# Cortex_M0PLUS register map
Vendor: ARM Ltd.; File version: 1.2
Cortex-M0+ core descriptions, generated from ARM develloper studio
CPU: CM0PLUS r0p0, little endian, MPU, no FPU, vendor SysTick, 8 interrupt priority bits
Registers are 32-bit, read-write, reset 0x0 unless marked. A register's access mark holds for its fields unless they carry their own. Offsets are from the block's base; lines under a group give offsets from that group; [hi:lo] are bit positions; {n}, {i} and the like mark numbered series; 'fields as' and 'values as' point back to an identical list; <NAME> marks a mode.

## Memory map
0xE000E010 STK size 0x10 — System Timer registers
0xE000E100 NVIC size 0x320 — Nested Vectored Interrupt Controller
0xE000ED00 SCB size 0x24 — System control block
0xE000ED04 Control size 0xE0 — System Control registers
0xE000ED90 MPU size 0x14 — Memory Protection Unit registers

## Control — System Control registers
Base 0xE000ED04
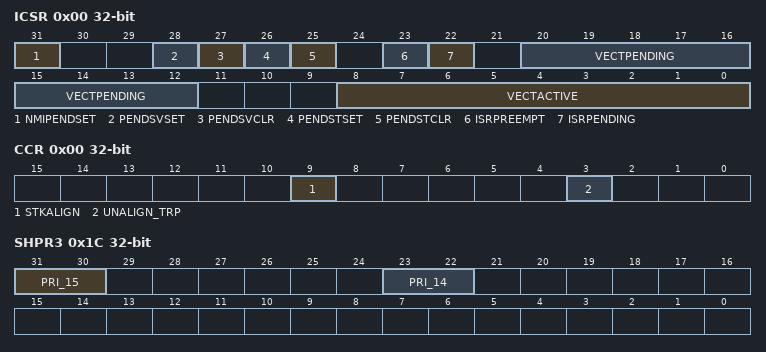
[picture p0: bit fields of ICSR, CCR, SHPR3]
0x00 ICSR reset not defined
  [31] NMIPENDSET
    0=Do_not_activate; 1=Activate_NMI_exception
  [28] PENDSVSET
    0=Do_not_set; 1=Set_pending
  [27] PENDSVCLR
    0=Do_not_clear; 1=Clear_pending
  [26] PENDSTSET
    0=Do_not_set; 1=Set_pending
  [25] PENDSTCLR
    0=Do_not_clear; 1=Clear_pending
  [23] ISRPREEMPT
    0=Will_not_service; 1=Will_service_pending_exception
  [22] ISRPENDING
    0=Interrupt_not_pending; 1=Interrupt_pending
  [20:12] VECTPENDING
  [8:0] VECTACTIVE
0x00 CCR ro reset not defined
  [9] STKALIGN, [3] UNALIGN_TRP
0x04 VTOR reset not defined
  [29] TBLBASE
    0=CODE; 1=SRAM
  [31:7] TBLOFF
0x08 AIRCR reset not defined
  [31:16] VECTKEY
  [31:16] VECTKEYSTAT
  [15] ENDIANNESS
    0=Little_endian; 1=Big_endian
  [2] SYSRESETREQ
    0=Do_not_request_reset; 1=Request_reset
  [1] VECTCLRACTIVE
    0=Do_not_clear; 1=Clear_state_information
0x18 SHPR2 reset not defined
  [31:30] PRI_11
0x1C SHPR3 reset not defined
  [31:30] PRI_15, [23:22] PRI_14
0x20 SHCSR reset not defined
  [15] SVCALLPENDED
    0=Not_pending; 1=Pending

## SCB — System control block
Base 0xE000ED00
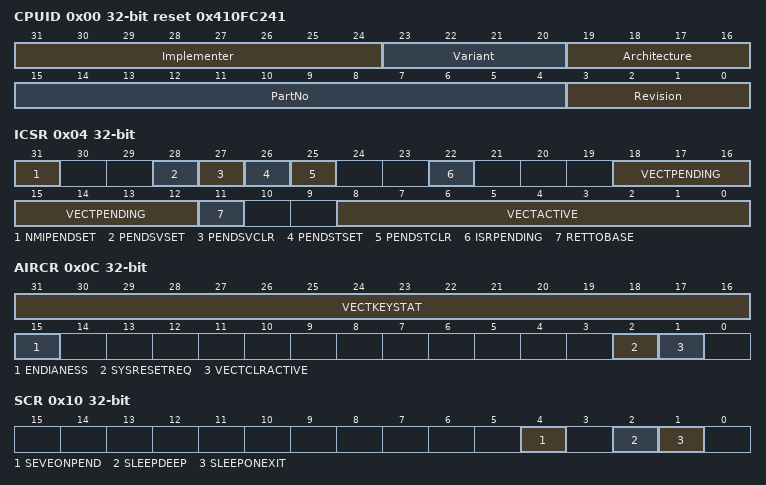
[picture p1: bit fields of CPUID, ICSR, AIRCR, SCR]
0x00 CPUID ro reset 0x410FC241 — CPUID base register
  [31:24] Implementer — Implementer code
  [23:20] Variant — Variant number
  [19:16] Architecture — Reads as 0xF
  [15:4] PartNo — Part number of the processor
  [3:0] Revision — Revision number
0x04 ICSR — Interrupt control and state register
  [31] NMIPENDSET — NMI set-pending bit.
  [28] PENDSVSET — PendSV set-pending bit
  [27] PENDSVCLR — PendSV clear-pending bit
  [26] PENDSTSET — SysTick exception set-pending bit
  [25] PENDSTCLR — SysTick exception clear-pending bit
  [22] ISRPENDING — Interrupt pending flag
  [18:12] VECTPENDING — Pending vector
  [11] RETTOBASE — Return to base level
  [8:0] VECTACTIVE — Active vector
0x08 VTOR — Vector table offset register
  [31:7] TBLOFF — Vector table base offset field
0x0C AIRCR — Application interrupt and reset control register
  [31:16] VECTKEYSTAT — Register key
  [15] ENDIANESS
  [2] SYSRESETREQ
  [1] VECTCLRACTIVE
0x10 SCR — System control register
  [4] SEVEONPEND — Send Event on Pending bit
  [2] SLEEPDEEP
  [1] SLEEPONEXIT
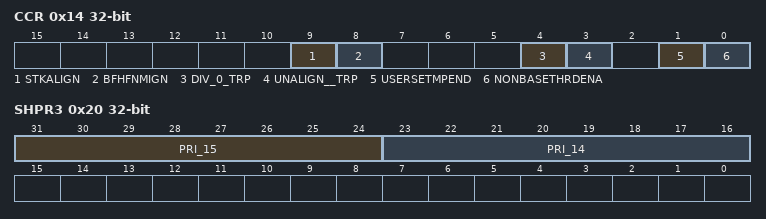
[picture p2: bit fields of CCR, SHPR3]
0x14 CCR — Configuration and control register
  [9] STKALIGN
  [8] BFHFNMIGN
  [4] DIV_0_TRP
  [3] UNALIGN__TRP
  [1] USERSETMPEND
  [0] NONBASETHRDENA — Configures how the processor enters Thread mode
0x1C SHPR2 — System handler priority registers
  [31:24] PRI_11 — Priority of system handler 11
0x20 SHPR3 — System handler priority registers
  [31:24] PRI_15 — Priority of system handler 15
  [23:16] PRI_14 — Priority of system handler 14

## MPU — Memory Protection Unit registers
Base 0xE000ED90
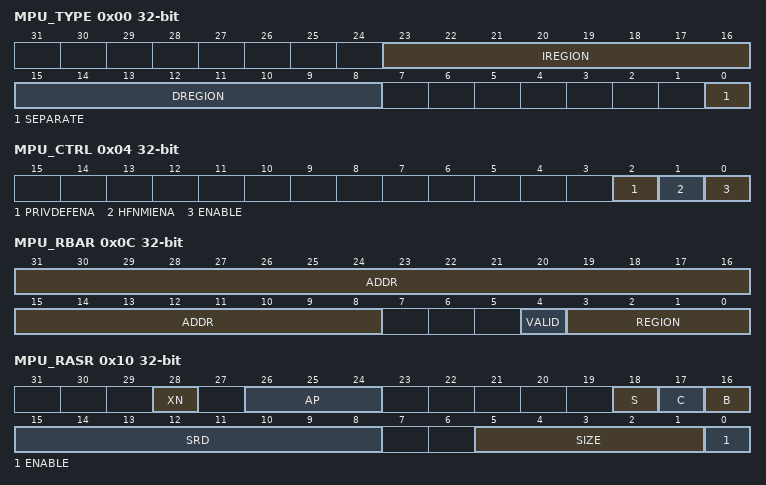
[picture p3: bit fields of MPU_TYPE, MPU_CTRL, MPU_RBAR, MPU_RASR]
0x00 MPU_TYPE ro reset not defined
  [23:16] IREGION, [15:8] DREGION, [0] SEPARATE
0x04 MPU_CTRL reset not defined — MPU Control Register
  [all] fields
    0=Disabled; 1=Enabled
  [2] PRIVDEFENA
  [1] HFNMIENA
  [0] ENABLE
0x08 MPU_RNR reset not defined — MPU Region Number Register
  [7:0] REGION
0x0C MPU_RBAR reset not defined — MPU Region Base Address Register
  [31:8] ADDR, [4] VALID, [3:0] REGION
0x10 MPU_RASR reset not defined — MPU Region Attribute and Size Register
  [28] XN
    0=Execution_permitted; 1=Execution_not_permitted
  [26:24] AP
    0=No_access; 1=Privileged_RW; 2=Privileged_RW_Unprivileged_RO; 3=Full_access; 5=Privileged_RO; 6=Privileged_RO_Unprivileged_RO; 7=Privileged_RO_Unprivileged_RO
  [18] S — Shareable memory attribute
  [17] C — memory attribute
  [16] B — memory attribute
  [15:8] SRD
  [5:1] SIZE
    7=_256B; 8=_512B; 9=_1KB; 10=_2KB; 11=_4KB; 12=_8KB; 13=_16KB; 14=_32KB; 15=_64KB; 16=_128KB; 17=_256KB; 18=_512KB; 19=_1MB; 20=_2MB; 21=_4MB; 22=_8MB; 23=_16MB; 24=_32MB; 25=_64MB; 26=_128MB; 27=_256MB; 28=_512MB; 29=_1GB; 30=_2GB; 31=_4GB
  [0] ENABLE
    0=Disabled; 1=Enabled

## NVIC — Nested Vectored Interrupt Controller
Base 0xE000E100
0x00 ISER — Interrupt Set Enable Register
  [31:0] SETENA
0x80 ICER — Interrupt Clear Enable Register
  [31:0] CLRENA
0x100 ISPR — Interrupt Set-Pending Register
  [31:0] SETPEND
0x180 ICPR — Interrupt Clear-Pending Register
  [31:0] CLRPEND
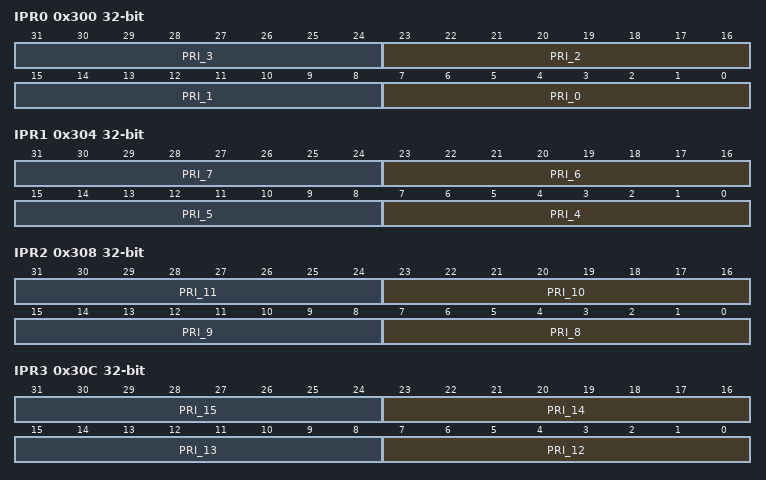
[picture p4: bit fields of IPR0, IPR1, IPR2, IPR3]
0x300 IPR0 — Interrupt Priority Register 0
  [8n+7:8n] PRI_{n} (n=0..3) — priority for interrupt {n}
0x304 IPR1 — Interrupt Priority Register 1
  [8n-25:8n-32] PRI_{n} (n=4..7) — priority for interrupt n
0x308 IPR2 — Interrupt Priority Register 2
  [8n-57:8n-64] PRI_{n} (n=8..11) — priority for interrupt n
0x30C IPR3 — Interrupt Priority Register 3
  [8n-89:8n-96] PRI_{n} (n=12..15) — priority for interrupt n
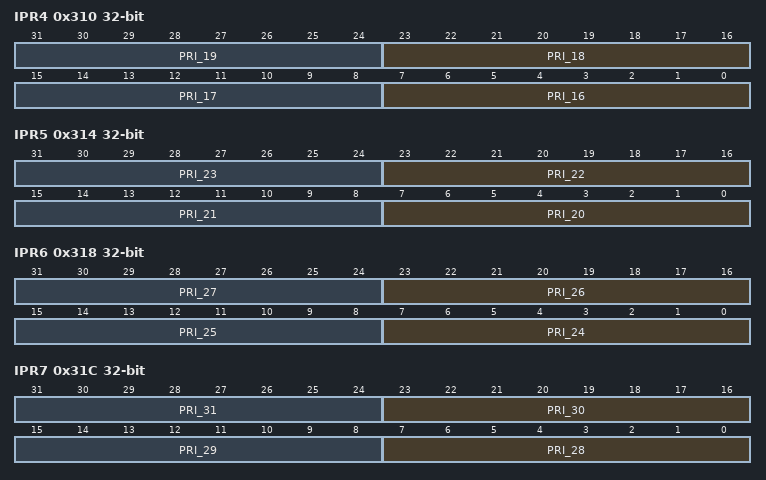
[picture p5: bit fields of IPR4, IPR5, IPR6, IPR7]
0x310 IPR4 — Interrupt Priority Register 4
  [8n-121:8n-128] PRI_{n} (n=16..19) — priority for interrupt n
0x314 IPR5 — Interrupt Priority Register 5
  [8n-153:8n-160] PRI_{n} (n=20..23) — priority for interrupt n
0x318 IPR6 — Interrupt Priority Register 6
  [8n-185:8n-192] PRI_{n} (n=24..27) — priority for interrupt n
0x31C IPR7 — Interrupt Priority Register 7
  [8n-217:8n-224] PRI_{n} (n=28..31) — priority for interrupt n

## STK — System Timer registers
Base 0xE000E010
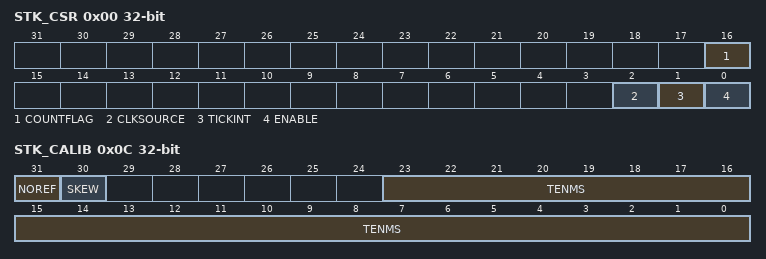
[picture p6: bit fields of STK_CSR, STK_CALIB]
0x00 STK_CSR reset not defined — SysTick control and status register
  [16] COUNTFLAG
    0=Not_counted_to_0; 1=Counted_to_0
  [2] CLKSOURCE — Clock source selection
    0=External_clock; 1=Processor_clock
  [1] TICKINT — SysTick exception request enable
    0=Does_not_affect_exception_status; 1=Changes_exception_status
  [0] ENABLE — Counter enable
    0=Counter_disabled; 1=Counter_operating
0x04 STK_RVR reset not defined — SysTick reload value register
  [23:0] RELOAD — RELOAD value
0x08 STK_CVR reset not defined — SysTick current value register
  [23:0] CURRENT
0x0C STK_CALIB reset not defined — SysTick calibration value register
  [31] NOREF — NOREF flag. Reads as zero
    0=Implemented; 1=Not_implemented
  [30] SKEW — SKEW flag: Indicates whether the TENMS value is exact
    0=Exact; 1=Inexact
  [23:0] TENMS — Calibration value

## Notices in the file
Copyright (c) 2023 STMicroelectronics.
SPDX-License-Identifier: Apache-2.0
Licensed under the Apache License, Version 2.0 (the "License");
you may not use this file except in compliance with the License.
You may obtain a copy of the License at
http://www.apache.org/licenses/LICENSE-2.0
Unless required by applicable law or agreed to in writing, software
distributed under the License is distributed on an "AS IS" BASIS,
WITHOUT WARRANTIES OR CONDITIONS OF ANY KIND, either express or implied.
See the License for the specific language governing permissions and
limitations under the License.
